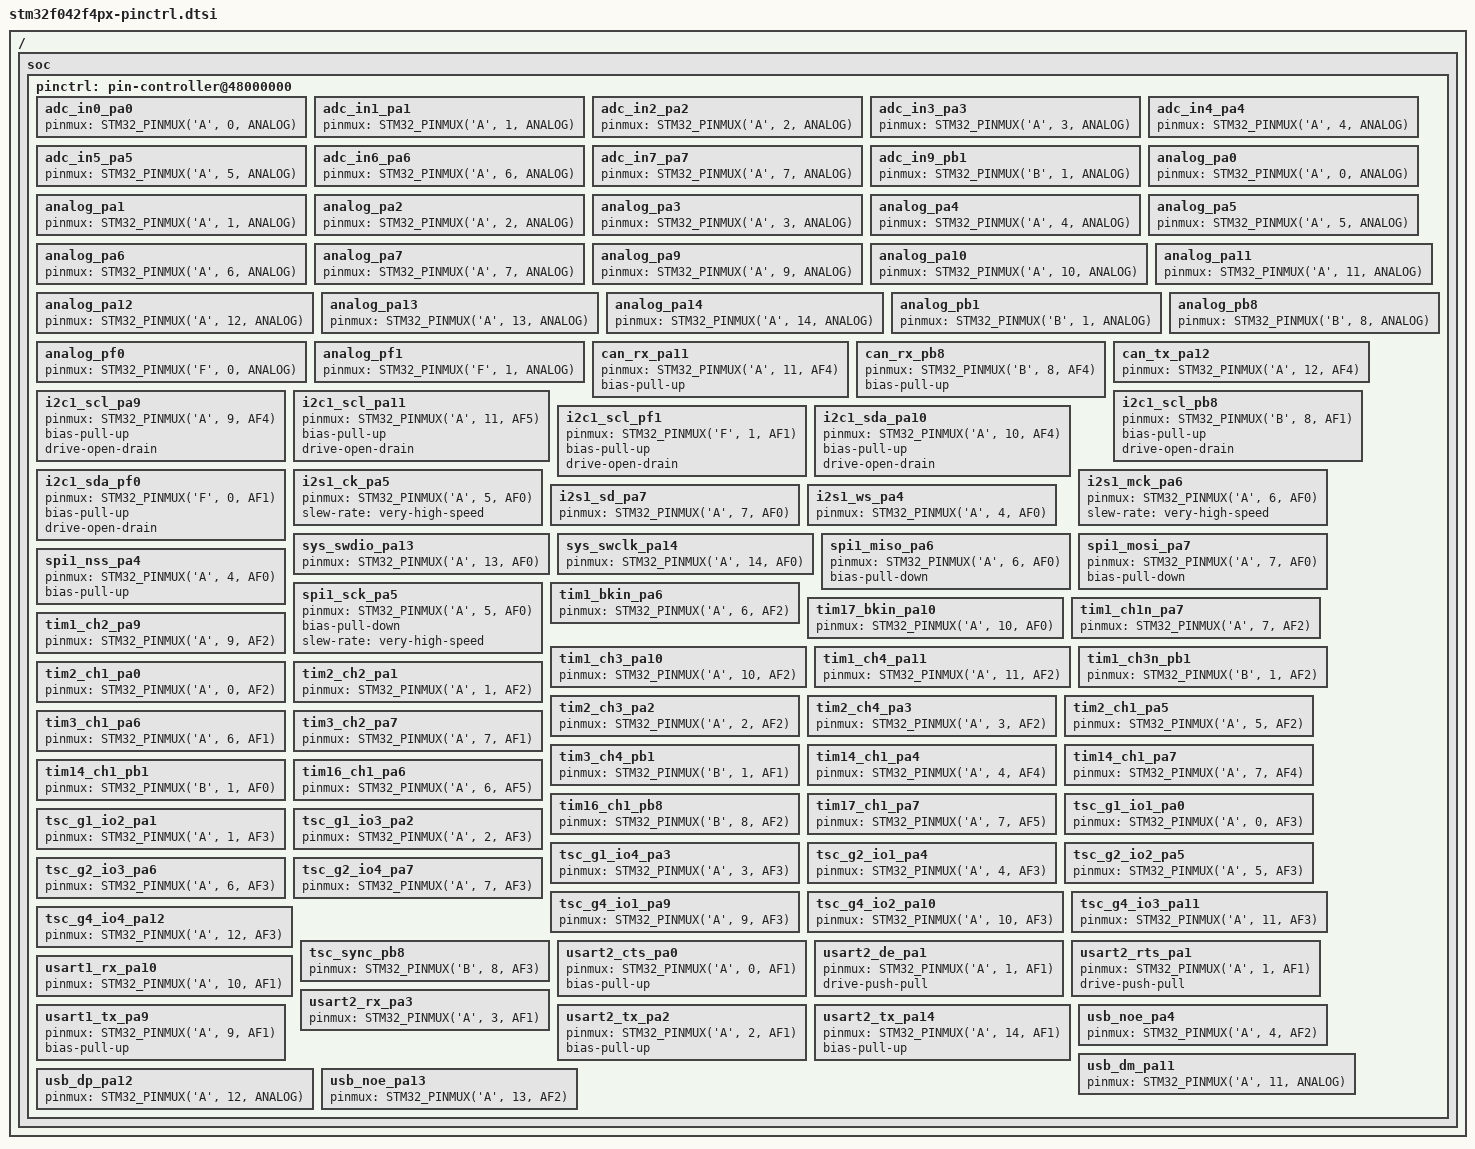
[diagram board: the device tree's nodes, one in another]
/*
 * NOTE: Autogenerated file using genpinctrl.py
 *
 * SPDX-License-Identifier: Apache-2.0
 */

#include <zephyr/dt-bindings/pinctrl/stm32-pinctrl.h>

/ {
	soc {
		pinctrl: pin-controller@48000000 {

			/* ADC_IN / ADC_INN / ADC_INP */

			/omit-if-no-ref/ adc_in0_pa0: adc_in0_pa0 {
				pinmux = <STM32_PINMUX('A', 0, ANALOG)>;
			};

			/omit-if-no-ref/ adc_in1_pa1: adc_in1_pa1 {
				pinmux = <STM32_PINMUX('A', 1, ANALOG)>;
			};

			/omit-if-no-ref/ adc_in2_pa2: adc_in2_pa2 {
				pinmux = <STM32_PINMUX('A', 2, ANALOG)>;
			};

			/omit-if-no-ref/ adc_in3_pa3: adc_in3_pa3 {
				pinmux = <STM32_PINMUX('A', 3, ANALOG)>;
			};

			/omit-if-no-ref/ adc_in4_pa4: adc_in4_pa4 {
				pinmux = <STM32_PINMUX('A', 4, ANALOG)>;
			};

			/omit-if-no-ref/ adc_in5_pa5: adc_in5_pa5 {
				pinmux = <STM32_PINMUX('A', 5, ANALOG)>;
			};

			/omit-if-no-ref/ adc_in6_pa6: adc_in6_pa6 {
				pinmux = <STM32_PINMUX('A', 6, ANALOG)>;
			};

			/omit-if-no-ref/ adc_in7_pa7: adc_in7_pa7 {
				pinmux = <STM32_PINMUX('A', 7, ANALOG)>;
			};

			/omit-if-no-ref/ adc_in9_pb1: adc_in9_pb1 {
				pinmux = <STM32_PINMUX('B', 1, ANALOG)>;
			};

			/* Analog */

			/omit-if-no-ref/ analog_pa0: analog_pa0 {
				pinmux = <STM32_PINMUX('A', 0, ANALOG)>;
			};

			/omit-if-no-ref/ analog_pa1: analog_pa1 {
				pinmux = <STM32_PINMUX('A', 1, ANALOG)>;
			};

			/omit-if-no-ref/ analog_pa2: analog_pa2 {
				pinmux = <STM32_PINMUX('A', 2, ANALOG)>;
			};

			/omit-if-no-ref/ analog_pa3: analog_pa3 {
				pinmux = <STM32_PINMUX('A', 3, ANALOG)>;
			};

			/omit-if-no-ref/ analog_pa4: analog_pa4 {
				pinmux = <STM32_PINMUX('A', 4, ANALOG)>;
			};

			/omit-if-no-ref/ analog_pa5: analog_pa5 {
				pinmux = <STM32_PINMUX('A', 5, ANALOG)>;
			};

			/omit-if-no-ref/ analog_pa6: analog_pa6 {
				pinmux = <STM32_PINMUX('A', 6, ANALOG)>;
			};

			/omit-if-no-ref/ analog_pa7: analog_pa7 {
				pinmux = <STM32_PINMUX('A', 7, ANALOG)>;
			};

			/omit-if-no-ref/ analog_pa9: analog_pa9 {
				pinmux = <STM32_PINMUX('A', 9, ANALOG)>;
			};

			/omit-if-no-ref/ analog_pa10: analog_pa10 {
				pinmux = <STM32_PINMUX('A', 10, ANALOG)>;
			};

			/omit-if-no-ref/ analog_pa11: analog_pa11 {
				pinmux = <STM32_PINMUX('A', 11, ANALOG)>;
			};

			/omit-if-no-ref/ analog_pa12: analog_pa12 {
				pinmux = <STM32_PINMUX('A', 12, ANALOG)>;
			};

			/omit-if-no-ref/ analog_pa13: analog_pa13 {
				pinmux = <STM32_PINMUX('A', 13, ANALOG)>;
			};

			/omit-if-no-ref/ analog_pa14: analog_pa14 {
				pinmux = <STM32_PINMUX('A', 14, ANALOG)>;
			};

			/omit-if-no-ref/ analog_pb1: analog_pb1 {
				pinmux = <STM32_PINMUX('B', 1, ANALOG)>;
			};

			/omit-if-no-ref/ analog_pb8: analog_pb8 {
				pinmux = <STM32_PINMUX('B', 8, ANALOG)>;
			};

			/omit-if-no-ref/ analog_pf0: analog_pf0 {
				pinmux = <STM32_PINMUX('F', 0, ANALOG)>;
			};

			/omit-if-no-ref/ analog_pf1: analog_pf1 {
				pinmux = <STM32_PINMUX('F', 1, ANALOG)>;
			};

			/* CAN_RX */

			/omit-if-no-ref/ can_rx_pa11: can_rx_pa11 {
				pinmux = <STM32_PINMUX('A', 11, AF4)>;
				bias-pull-up;
			};

			/omit-if-no-ref/ can_rx_pb8: can_rx_pb8 {
				pinmux = <STM32_PINMUX('B', 8, AF4)>;
				bias-pull-up;
			};

			/* CAN_TX */

			/omit-if-no-ref/ can_tx_pa12: can_tx_pa12 {
				pinmux = <STM32_PINMUX('A', 12, AF4)>;
			};

			/* I2C_SCL */

			/omit-if-no-ref/ i2c1_scl_pa9: i2c1_scl_pa9 {
				pinmux = <STM32_PINMUX('A', 9, AF4)>;
				bias-pull-up;
				drive-open-drain;
			};

			/omit-if-no-ref/ i2c1_scl_pa11: i2c1_scl_pa11 {
				pinmux = <STM32_PINMUX('A', 11, AF5)>;
				bias-pull-up;
				drive-open-drain;
			};

			/omit-if-no-ref/ i2c1_scl_pb8: i2c1_scl_pb8 {
				pinmux = <STM32_PINMUX('B', 8, AF1)>;
				bias-pull-up;
				drive-open-drain;
			};

			/omit-if-no-ref/ i2c1_scl_pf1: i2c1_scl_pf1 {
				pinmux = <STM32_PINMUX('F', 1, AF1)>;
				bias-pull-up;
				drive-open-drain;
			};

			/* I2C_SDA */

			/omit-if-no-ref/ i2c1_sda_pa10: i2c1_sda_pa10 {
				pinmux = <STM32_PINMUX('A', 10, AF4)>;
				bias-pull-up;
				drive-open-drain;
			};

			/omit-if-no-ref/ i2c1_sda_pf0: i2c1_sda_pf0 {
				pinmux = <STM32_PINMUX('F', 0, AF1)>;
				bias-pull-up;
				drive-open-drain;
			};

			/* I2S_CK */

			/omit-if-no-ref/ i2s1_ck_pa5: i2s1_ck_pa5 {
				pinmux = <STM32_PINMUX('A', 5, AF0)>;
				slew-rate = "very-high-speed";
			};

			/* I2S_MCK */

			/omit-if-no-ref/ i2s1_mck_pa6: i2s1_mck_pa6 {
				pinmux = <STM32_PINMUX('A', 6, AF0)>;
				slew-rate = "very-high-speed";
			};

			/* I2S_SD */

			/omit-if-no-ref/ i2s1_sd_pa7: i2s1_sd_pa7 {
				pinmux = <STM32_PINMUX('A', 7, AF0)>;
			};

			/* I2S_WS */

			/omit-if-no-ref/ i2s1_ws_pa4: i2s1_ws_pa4 {
				pinmux = <STM32_PINMUX('A', 4, AF0)>;
			};

			/* JTAG PORT */

			/omit-if-no-ref/ sys_swdio_pa13: sys_swdio_pa13 {
				pinmux = <STM32_PINMUX('A', 13, AF0)>;
			};

			/omit-if-no-ref/ sys_swclk_pa14: sys_swclk_pa14 {
				pinmux = <STM32_PINMUX('A', 14, AF0)>;
			};

			/* SPI_MISO */

			/omit-if-no-ref/ spi1_miso_pa6: spi1_miso_pa6 {
				pinmux = <STM32_PINMUX('A', 6, AF0)>;
				bias-pull-down;
			};

			/* SPI_MOSI */

			/omit-if-no-ref/ spi1_mosi_pa7: spi1_mosi_pa7 {
				pinmux = <STM32_PINMUX('A', 7, AF0)>;
				bias-pull-down;
			};

			/* SPI_NSS */

			/omit-if-no-ref/ spi1_nss_pa4: spi1_nss_pa4 {
				pinmux = <STM32_PINMUX('A', 4, AF0)>;
				bias-pull-up;
			};

			/* SPI_SCK */

			/omit-if-no-ref/ spi1_sck_pa5: spi1_sck_pa5 {
				pinmux = <STM32_PINMUX('A', 5, AF0)>;
				bias-pull-down;
				slew-rate = "very-high-speed";
			};

			/* TIM_BKIN */

			/omit-if-no-ref/ tim1_bkin_pa6: tim1_bkin_pa6 {
				pinmux = <STM32_PINMUX('A', 6, AF2)>;
			};

			/omit-if-no-ref/ tim17_bkin_pa10: tim17_bkin_pa10 {
				pinmux = <STM32_PINMUX('A', 10, AF0)>;
			};

			/* TIM_CH / TIM_CHN */

			/omit-if-no-ref/ tim1_ch1n_pa7: tim1_ch1n_pa7 {
				pinmux = <STM32_PINMUX('A', 7, AF2)>;
			};

			/omit-if-no-ref/ tim1_ch2_pa9: tim1_ch2_pa9 {
				pinmux = <STM32_PINMUX('A', 9, AF2)>;
			};

			/omit-if-no-ref/ tim1_ch3_pa10: tim1_ch3_pa10 {
				pinmux = <STM32_PINMUX('A', 10, AF2)>;
			};

			/omit-if-no-ref/ tim1_ch4_pa11: tim1_ch4_pa11 {
				pinmux = <STM32_PINMUX('A', 11, AF2)>;
			};

			/omit-if-no-ref/ tim1_ch3n_pb1: tim1_ch3n_pb1 {
				pinmux = <STM32_PINMUX('B', 1, AF2)>;
			};

			/omit-if-no-ref/ tim2_ch1_pa0: tim2_ch1_pa0 {
				pinmux = <STM32_PINMUX('A', 0, AF2)>;
			};

			/omit-if-no-ref/ tim2_ch2_pa1: tim2_ch2_pa1 {
				pinmux = <STM32_PINMUX('A', 1, AF2)>;
			};

			/omit-if-no-ref/ tim2_ch3_pa2: tim2_ch3_pa2 {
				pinmux = <STM32_PINMUX('A', 2, AF2)>;
			};

			/omit-if-no-ref/ tim2_ch4_pa3: tim2_ch4_pa3 {
				pinmux = <STM32_PINMUX('A', 3, AF2)>;
			};

			/omit-if-no-ref/ tim2_ch1_pa5: tim2_ch1_pa5 {
				pinmux = <STM32_PINMUX('A', 5, AF2)>;
			};

			/omit-if-no-ref/ tim3_ch1_pa6: tim3_ch1_pa6 {
				pinmux = <STM32_PINMUX('A', 6, AF1)>;
			};

			/omit-if-no-ref/ tim3_ch2_pa7: tim3_ch2_pa7 {
				pinmux = <STM32_PINMUX('A', 7, AF1)>;
			};

			/omit-if-no-ref/ tim3_ch4_pb1: tim3_ch4_pb1 {
				pinmux = <STM32_PINMUX('B', 1, AF1)>;
			};

			/omit-if-no-ref/ tim14_ch1_pa4: tim14_ch1_pa4 {
				pinmux = <STM32_PINMUX('A', 4, AF4)>;
			};

			/omit-if-no-ref/ tim14_ch1_pa7: tim14_ch1_pa7 {
				pinmux = <STM32_PINMUX('A', 7, AF4)>;
			};

			/omit-if-no-ref/ tim14_ch1_pb1: tim14_ch1_pb1 {
				pinmux = <STM32_PINMUX('B', 1, AF0)>;
			};

			/omit-if-no-ref/ tim16_ch1_pa6: tim16_ch1_pa6 {
				pinmux = <STM32_PINMUX('A', 6, AF5)>;
			};

			/omit-if-no-ref/ tim16_ch1_pb8: tim16_ch1_pb8 {
				pinmux = <STM32_PINMUX('B', 8, AF2)>;
			};

			/omit-if-no-ref/ tim17_ch1_pa7: tim17_ch1_pa7 {
				pinmux = <STM32_PINMUX('A', 7, AF5)>;
			};

			/* TSC */

			/omit-if-no-ref/ tsc_g1_io1_pa0: tsc_g1_io1_pa0 {
				pinmux = <STM32_PINMUX('A', 0, AF3)>;
			};

			/omit-if-no-ref/ tsc_g1_io2_pa1: tsc_g1_io2_pa1 {
				pinmux = <STM32_PINMUX('A', 1, AF3)>;
			};

			/omit-if-no-ref/ tsc_g1_io3_pa2: tsc_g1_io3_pa2 {
				pinmux = <STM32_PINMUX('A', 2, AF3)>;
			};

			/omit-if-no-ref/ tsc_g1_io4_pa3: tsc_g1_io4_pa3 {
				pinmux = <STM32_PINMUX('A', 3, AF3)>;
			};

			/omit-if-no-ref/ tsc_g2_io1_pa4: tsc_g2_io1_pa4 {
				pinmux = <STM32_PINMUX('A', 4, AF3)>;
			};

			/omit-if-no-ref/ tsc_g2_io2_pa5: tsc_g2_io2_pa5 {
				pinmux = <STM32_PINMUX('A', 5, AF3)>;
			};

			/omit-if-no-ref/ tsc_g2_io3_pa6: tsc_g2_io3_pa6 {
				pinmux = <STM32_PINMUX('A', 6, AF3)>;
			};

			/omit-if-no-ref/ tsc_g2_io4_pa7: tsc_g2_io4_pa7 {
				pinmux = <STM32_PINMUX('A', 7, AF3)>;
			};

			/omit-if-no-ref/ tsc_g4_io1_pa9: tsc_g4_io1_pa9 {
				pinmux = <STM32_PINMUX('A', 9, AF3)>;
			};

			/omit-if-no-ref/ tsc_g4_io2_pa10: tsc_g4_io2_pa10 {
				pinmux = <STM32_PINMUX('A', 10, AF3)>;
			};

			/omit-if-no-ref/ tsc_g4_io3_pa11: tsc_g4_io3_pa11 {
				pinmux = <STM32_PINMUX('A', 11, AF3)>;
			};

			/omit-if-no-ref/ tsc_g4_io4_pa12: tsc_g4_io4_pa12 {
				pinmux = <STM32_PINMUX('A', 12, AF3)>;
			};

			/omit-if-no-ref/ tsc_sync_pb8: tsc_sync_pb8 {
				pinmux = <STM32_PINMUX('B', 8, AF3)>;
			};

			/* UART_CTS / USART_CTS / LPUART_CTS */

			/omit-if-no-ref/ usart2_cts_pa0: usart2_cts_pa0 {
				pinmux = <STM32_PINMUX('A', 0, AF1)>;
				bias-pull-up;
			};

			/* UART_DE / USART_DE / LPUART_DE */

			/omit-if-no-ref/ usart2_de_pa1: usart2_de_pa1 {
				pinmux = <STM32_PINMUX('A', 1, AF1)>;
				drive-push-pull;
			};

			/* UART_RTS / USART_RTS / LPUART_RTS */

			/omit-if-no-ref/ usart2_rts_pa1: usart2_rts_pa1 {
				pinmux = <STM32_PINMUX('A', 1, AF1)>;
				drive-push-pull;
			};

			/* UART_RX / USART_RX / LPUART_RX */

			/omit-if-no-ref/ usart1_rx_pa10: usart1_rx_pa10 {
				pinmux = <STM32_PINMUX('A', 10, AF1)>;
			};

			/omit-if-no-ref/ usart2_rx_pa3: usart2_rx_pa3 {
				pinmux = <STM32_PINMUX('A', 3, AF1)>;
			};

			/* UART_TX / USART_TX / LPUART_TX */

			/omit-if-no-ref/ usart1_tx_pa9: usart1_tx_pa9 {
				pinmux = <STM32_PINMUX('A', 9, AF1)>;
				bias-pull-up;
			};

			/omit-if-no-ref/ usart2_tx_pa2: usart2_tx_pa2 {
				pinmux = <STM32_PINMUX('A', 2, AF1)>;
				bias-pull-up;
			};

			/omit-if-no-ref/ usart2_tx_pa14: usart2_tx_pa14 {
				pinmux = <STM32_PINMUX('A', 14, AF1)>;
				bias-pull-up;
			};

			/* USB */

			/omit-if-no-ref/ usb_noe_pa4: usb_noe_pa4 {
				pinmux = <STM32_PINMUX('A', 4, AF2)>;
			};

			/omit-if-no-ref/ usb_dm_pa11: usb_dm_pa11 {
				pinmux = <STM32_PINMUX('A', 11, ANALOG)>;
			};

			/omit-if-no-ref/ usb_dp_pa12: usb_dp_pa12 {
				pinmux = <STM32_PINMUX('A', 12, ANALOG)>;
			};

			/omit-if-no-ref/ usb_noe_pa13: usb_noe_pa13 {
				pinmux = <STM32_PINMUX('A', 13, AF2)>;
			};

		};
	};
};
